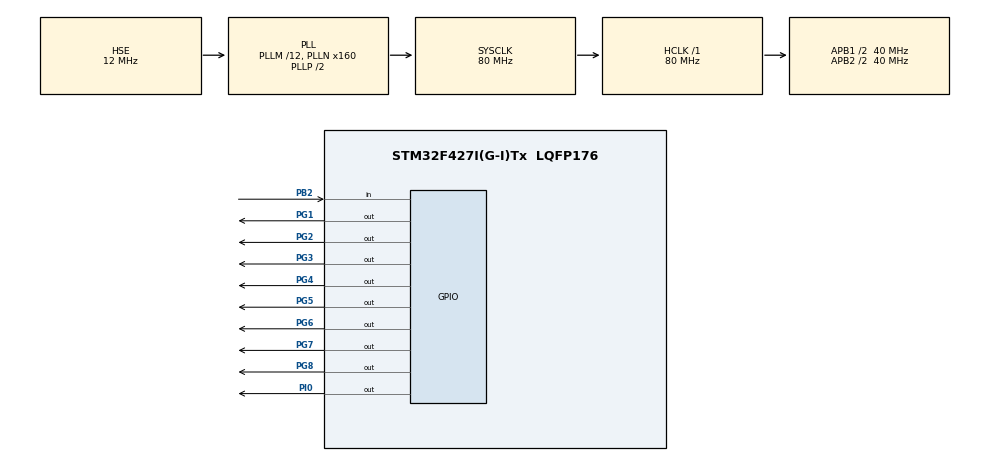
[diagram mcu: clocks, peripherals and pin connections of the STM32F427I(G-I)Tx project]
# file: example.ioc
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Mcu.Family=STM32F4
Mcu.Name=STM32F427I(G-I)Tx
Mcu.Package=LQFP176
NVIC.PriorityGroup=NVIC_PRIORITYGROUP_4
PB2/BOOT1.GPIO_PuPd=GPIO_PULLDOWN
PB2/BOOT1.Signal=GPIO_Input
PG1.Signal=GPIO_Output
PG2.Signal=GPIO_Output
PG3.Signal=GPIO_Output
PG4.Signal=GPIO_Output
PG5.Signal=GPIO_Output
PG6.Signal=GPIO_Output
PG7.Signal=GPIO_Output
PG8.Signal=GPIO_Output
PH0/OSC_IN.Mode=HSE-External-Oscillator
PH0/OSC_IN.Signal=RCC_OSC_IN
PH1/OSC_OUT.Mode=HSE-External-Oscillator
PH1/OSC_OUT.Signal=RCC_OSC_OUT
PI0.Signal=GPIO_Output
ProjectManager.HeapSize=0x200
ProjectManager.StackSize=0x400
ProjectManager.TargetToolchain=MDK-ARM V5
RCC.48MHZClocksFreq_Value=40000000
RCC.AHBFreq_Value=80000000
RCC.APB1CLKDivider=RCC_HCLK_DIV2
RCC.APB1Freq_Value=40000000
RCC.APB1TimFreq_Value=80000000
RCC.APB2CLKDivider=RCC_HCLK_DIV2
RCC.APB2Freq_Value=40000000
RCC.APB2TimFreq_Value=80000000
RCC.CortexFreq_Value=80000000
RCC.HCLKFreq_Value=80000000
RCC.HSE_VALUE=12000000
RCC.HSI_VALUE=16000000
RCC.LSE_VALUE=32768
RCC.PLLM=12
RCC.PLLN=160
RCC.PLLSourceVirtual=RCC_PLLSOURCE_HSE
RCC.SYSCLKFreq_VALUE=80000000
RCC.SYSCLKSource=RCC_SYSCLKSOURCE_PLLCLK
RCC.VCOOutputFreq_Value=160000000
TIM7.Period=65535
TIM7.Prescaler=1
VP_TIM7_VS_ClockSourceINT.Mode=Enable_Timer
board=custom

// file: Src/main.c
/* USER CODE BEGIN Header */
/**
  ******************************************************************************
  * @file           : main.c
  * @brief          : Main program body
  ******************************************************************************
  * @attention
  *
  * <h2><center>&copy; Copyright (c) 2019 STMicroelectronics.
  * All rights reserved.</center></h2>
  *
  * This software component is licensed by ST under BSD 3-Clause license,
  * the "License"; You may not use this file except in compliance with the
  * License. You may obtain a copy of the License at:
  *                        opensource.org/licenses/BSD-3-Clause
  *
  ******************************************************************************
  */
/* USER CODE END Header */

#include "main.h"
#include "tim.h"
#include "gpio.h"

void SystemClock_Config(void);
/* USER CODE BEGIN PFP */
void tim_delay_us(uint16_t us);
/* USER CODE END PFP */

int main(void)
{

  /* MCU Configuration--------------------------------------------------------*/

  /* Reset of all peripherals, Initializes the Flash interface and the Systick. */
  HAL_Init();

  /* Configure the system clock */
  SystemClock_Config();

  /* Initialize all configured peripherals */
  MX_GPIO_Init();
  MX_TIM7_Init();
  /* USER CODE BEGIN 2 */
	HAL_TIM_Base_Start(&htim7);
  /* USER CODE END 2 */

  /* Infinite loop */
  while (1)
  {

    /* USER CODE BEGIN 3 */
		HAL_GPIO_TogglePin(GPIOI, GPIO_PIN_0);
		tim_delay_us(50);

  }
  /* USER CODE END 3 */
}

void SystemClock_Config(void)
{
  RCC_OscInitTypeDef RCC_OscInitStruct = {0};
  RCC_ClkInitTypeDef RCC_ClkInitStruct = {0};

  /** Configure the main internal regulator output voltage
  */
  __HAL_RCC_PWR_CLK_ENABLE();
  __HAL_PWR_VOLTAGESCALING_CONFIG(PWR_REGULATOR_VOLTAGE_SCALE3);
  /** Initializes the CPU, AHB and APB busses clocks
  */
  RCC_OscInitStruct.OscillatorType = RCC_OSCILLATORTYPE_HSE;
  RCC_OscInitStruct.HSEState = RCC_HSE_ON;
  RCC_OscInitStruct.PLL.PLLState = RCC_PLL_ON;
  RCC_OscInitStruct.PLL.PLLSource = RCC_PLLSOURCE_HSE;
  RCC_OscInitStruct.PLL.PLLM = 12;
  RCC_OscInitStruct.PLL.PLLN = 160;
  RCC_OscInitStruct.PLL.PLLP = RCC_PLLP_DIV2;
  RCC_OscInitStruct.PLL.PLLQ = 4;
  if (HAL_RCC_OscConfig(&RCC_OscInitStruct) != HAL_OK)
  {
    Error_Handler();
  }
  /** Initializes the CPU, AHB and APB busses clocks
  */
  RCC_ClkInitStruct.ClockType = RCC_CLOCKTYPE_HCLK|RCC_CLOCKTYPE_SYSCLK
                              |RCC_CLOCKTYPE_PCLK1|RCC_CLOCKTYPE_PCLK2;
  RCC_ClkInitStruct.SYSCLKSource = RCC_SYSCLKSOURCE_PLLCLK;
  RCC_ClkInitStruct.AHBCLKDivider = RCC_SYSCLK_DIV1;
  RCC_ClkInitStruct.APB1CLKDivider = RCC_HCLK_DIV2;
  RCC_ClkInitStruct.APB2CLKDivider = RCC_HCLK_DIV2;

  if (HAL_RCC_ClockConfig(&RCC_ClkInitStruct, FLASH_LATENCY_2) != HAL_OK)
  {
    Error_Handler();
  }
}

/* USER CODE BEGIN 4 */
void tim_delay_us(uint16_t us)
{
//	HAL_TIM_Base_Start_IT(&htim7);
	__HAL_TIM_SetCounter(&htim7,5);
	while(__HAL_TIM_GetCounter(&htim7) < 40*us+5);
//	HAL_TIM_Base_Stop_IT(&htim7);
}

/* USER CODE END 4 */

void Error_Handler(void)
{
}

/************************ (C) COPYRIGHT STMicroelectronics *****END OF FILE****/
